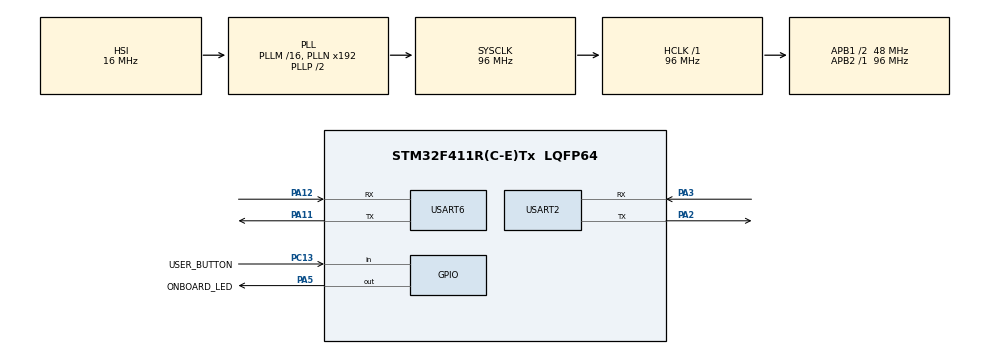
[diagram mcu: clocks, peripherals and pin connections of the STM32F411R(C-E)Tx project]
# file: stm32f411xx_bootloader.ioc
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Mcu.Family=STM32F4
Mcu.Name=STM32F411R(C-E)Tx
Mcu.Package=LQFP64
NVIC.PriorityGroup=NVIC_PRIORITYGROUP_4
PA11.Mode=Asynchronous
PA11.Signal=USART6_TX
PA12.Mode=Asynchronous
PA12.Signal=USART6_RX
PA2.Mode=Asynchronous
PA2.Signal=USART2_TX
PA3.Mode=Asynchronous
PA3.Signal=USART2_RX
PA5.GPIO_Label=ONBOARD_LED
PA5.Signal=GPIO_Output
PC13-ANTI_TAMP.GPIO_Label=USER_BUTTON
PC13-ANTI_TAMP.GPIO_PuPd=GPIO_PULLUP
PC13-ANTI_TAMP.Signal=GPIO_Input
ProjectManager.HeapSize=0x200
ProjectManager.StackSize=0x400
ProjectManager.TargetToolchain=STM32CubeIDE
RCC.AHBFreq_Value=96000000
RCC.APB1CLKDivider=RCC_HCLK_DIV2
RCC.APB1Freq_Value=48000000
RCC.APB1TimFreq_Value=96000000
RCC.APB2Freq_Value=96000000
RCC.APB2TimFreq_Value=96000000
RCC.CortexFreq_Value=96000000
RCC.HCLKFreq_Value=96000000
RCC.HSE_VALUE=25000000
RCC.HSI_VALUE=16000000
RCC.LSE_VALUE=32768
RCC.SYSCLKFreq_VALUE=96000000
RCC.SYSCLKSource=RCC_SYSCLKSOURCE_PLLCLK
RCC.VCOOutputFreq_Value=192000000
USART2.VirtualMode=VM_ASYNC
USART6.VirtualMode=VM_ASYNC
VP_CRC_VS_CRC.Mode=CRC_Activate
board=custom

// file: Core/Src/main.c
/* USER CODE BEGIN Header */
/**
  ******************************************************************************
  * @file           : main.c
  * @brief          : Main program body
  ******************************************************************************
  * @attention
  *
  * <h2><center>&copy; Copyright (c) 2023 STMicroelectronics.
  * All rights reserved.</center></h2>
  *
  * This software component is licensed by ST under BSD 3-Clause license,
  * the "License"; You may not use this file except in compliance with the
  * License. You may obtain a copy of the License at:
  *                        opensource.org/licenses/BSD-3-Clause
  *
  ******************************************************************************
  */
/* USER CODE END Header */
#include "main.h"

/* USER CODE BEGIN PM */
#define DBG_UART	&huart6
/* USER CODE END PM */

CRC_HandleTypeDef hcrc;

UART_HandleTypeDef huart2;
UART_HandleTypeDef huart6;

void SystemClock_Config(void);
static void MX_GPIO_Init(void);
static void MX_USART2_UART_Init(void);
static void MX_USART6_UART_Init(void);
static void MX_CRC_Init(void);
/* USER CODE BEGIN PFP */
#ifdef BL_DEBUG_PRINTF
static void print_dbg_msg(char *format, ...);
#endif
/* USER CODE END PFP */

int main(void)
{
  /* MCU Configuration--------------------------------------------------------*/

  /* Reset of all peripherals, Initializes the Flash interface and the Systick. */
  HAL_Init();

  /* Configure the system clock */
  SystemClock_Config();

  /* Initialize all configured peripherals */
  MX_GPIO_Init();
  MX_USART2_UART_Init();
  MX_USART6_UART_Init();
  MX_CRC_Init();

  if(HAL_GPIO_ReadPin(USER_BUTTON_GPIO_Port, USER_BUTTON_Pin) == GPIO_PIN_RESET)
  {
#ifdef BL_DEBUG_PRINTF
	  print_dbg_msg("Entering the bootloader...\r\n");
#endif
	  bootloader_read_data();
  }
  else
  {
#ifdef BL_DEBUG_PRINTF
	  print_dbg_msg("Entering the user application...\r\n");
#endif
	  bootloader_jump_to_user_app();
  }
}

void SystemClock_Config(void)
{
  RCC_OscInitTypeDef RCC_OscInitStruct = {0};
  RCC_ClkInitTypeDef RCC_ClkInitStruct = {0};

  /** Configure the main internal regulator output voltage
  */
  __HAL_RCC_PWR_CLK_ENABLE();
  __HAL_PWR_VOLTAGESCALING_CONFIG(PWR_REGULATOR_VOLTAGE_SCALE1);
  /** Initializes the RCC Oscillators according to the specified parameters
  * in the RCC_OscInitTypeDef structure.
  */
  RCC_OscInitStruct.OscillatorType = RCC_OSCILLATORTYPE_HSI;
  RCC_OscInitStruct.HSIState = RCC_HSI_ON;
  RCC_OscInitStruct.HSICalibrationValue = RCC_HSICALIBRATION_DEFAULT;
  RCC_OscInitStruct.PLL.PLLState = RCC_PLL_ON;
  RCC_OscInitStruct.PLL.PLLSource = RCC_PLLSOURCE_HSI;
  RCC_OscInitStruct.PLL.PLLM = 16;
  RCC_OscInitStruct.PLL.PLLN = 192;
  RCC_OscInitStruct.PLL.PLLP = RCC_PLLP_DIV2;
  RCC_OscInitStruct.PLL.PLLQ = 4;
  if (HAL_RCC_OscConfig(&RCC_OscInitStruct) != HAL_OK)
  {
    Error_Handler();
  }
  /** Initializes the CPU, AHB and APB buses clocks
  */
  RCC_ClkInitStruct.ClockType = RCC_CLOCKTYPE_HCLK|RCC_CLOCKTYPE_SYSCLK
                              |RCC_CLOCKTYPE_PCLK1|RCC_CLOCKTYPE_PCLK2;
  RCC_ClkInitStruct.SYSCLKSource = RCC_SYSCLKSOURCE_PLLCLK;
  RCC_ClkInitStruct.AHBCLKDivider = RCC_SYSCLK_DIV1;
  RCC_ClkInitStruct.APB1CLKDivider = RCC_HCLK_DIV2;
  RCC_ClkInitStruct.APB2CLKDivider = RCC_HCLK_DIV1;

  if (HAL_RCC_ClockConfig(&RCC_ClkInitStruct, FLASH_LATENCY_3) != HAL_OK)
  {
    Error_Handler();
  }
}

static void MX_CRC_Init(void)
{

  hcrc.Instance = CRC;
  if (HAL_CRC_Init(&hcrc) != HAL_OK)
  {
    Error_Handler();
  }

}

static void MX_USART2_UART_Init(void)
{

  huart2.Instance = USART2;
  huart2.Init.BaudRate = 115200;
  huart2.Init.WordLength = UART_WORDLENGTH_8B;
  huart2.Init.StopBits = UART_STOPBITS_1;
  huart2.Init.Parity = UART_PARITY_NONE;
  huart2.Init.Mode = UART_MODE_TX_RX;
  huart2.Init.HwFlowCtl = UART_HWCONTROL_NONE;
  huart2.Init.OverSampling = UART_OVERSAMPLING_16;
  if (HAL_UART_Init(&huart2) != HAL_OK)
  {
    Error_Handler();
  }

}

static void MX_USART6_UART_Init(void)
{

  huart6.Instance = USART6;
  huart6.Init.BaudRate = 115200;
  huart6.Init.WordLength = UART_WORDLENGTH_8B;
  huart6.Init.StopBits = UART_STOPBITS_1;
  huart6.Init.Parity = UART_PARITY_NONE;
  huart6.Init.Mode = UART_MODE_TX_RX;
  huart6.Init.HwFlowCtl = UART_HWCONTROL_NONE;
  huart6.Init.OverSampling = UART_OVERSAMPLING_16;
  if (HAL_UART_Init(&huart6) != HAL_OK)
  {
    Error_Handler();
  }

}

static void MX_GPIO_Init(void)
{
  GPIO_InitTypeDef GPIO_InitStruct = {0};

  /* GPIO Ports Clock Enable */
  __HAL_RCC_GPIOC_CLK_ENABLE();
  __HAL_RCC_GPIOA_CLK_ENABLE();

  /*Configure GPIO pin Output Level */
  HAL_GPIO_WritePin(ONBOARD_LED_GPIO_Port, ONBOARD_LED_Pin, GPIO_PIN_RESET);

  /*Configure GPIO pin : USER_BUTTON_Pin */
  GPIO_InitStruct.Pin = USER_BUTTON_Pin;
  GPIO_InitStruct.Mode = GPIO_MODE_INPUT;
  GPIO_InitStruct.Pull = GPIO_PULLUP;
  HAL_GPIO_Init(USER_BUTTON_GPIO_Port, &GPIO_InitStruct);

  /*Configure GPIO pin : ONBOARD_LED_Pin */
  GPIO_InitStruct.Pin = ONBOARD_LED_Pin;
  GPIO_InitStruct.Mode = GPIO_MODE_OUTPUT_PP;
  GPIO_InitStruct.Pull = GPIO_NOPULL;
  GPIO_InitStruct.Speed = GPIO_SPEED_FREQ_LOW;
  HAL_GPIO_Init(ONBOARD_LED_GPIO_Port, &GPIO_InitStruct);

}

/* USER CODE BEGIN 4 */

#ifdef BL_DEBUG_PRINTF
static void print_dbg_msg(char *format, ...)
{
	char msg[80];

	/* Extract the argument list */
	va_list args;
	va_start(args, format);
	vsprintf(msg, format, args);

	/* Transmit the formatted string via DBG_UART */
	HAL_UART_Transmit(DBG_UART, (uint8_t *)msg, strlen(msg), HAL_MAX_DELAY);

	va_end(args);
}
#endif
/* USER CODE END 4 */

void Error_Handler(void)
{
  __disable_irq();
  while (1)
  {
  }
}

/************************ (C) COPYRIGHT STMicroelectronics *****END OF FILE****/
